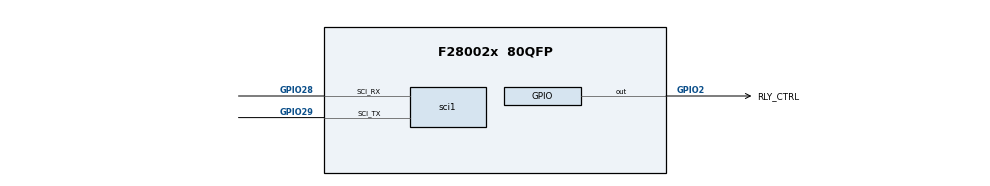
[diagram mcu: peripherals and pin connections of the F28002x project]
/**
 * @cliArgs --device "F28002x" --part "F28002x_80QFP" --package "80QFP" --context "system" --product "C2000WARE@5.04.00.00"
 * @versions {"tool":"1.23.0+4000"}
 */

/**
 * Import the modules used in this configuration.
 */
const adc     = scripting.addModule("/driverlib/adc.js", {}, false);
const adc1    = adc.addInstance();
const adc2    = adc.addInstance();
const asysctl = scripting.addModule("/driverlib/asysctl.js");
const gpio    = scripting.addModule("/driverlib/gpio.js", {}, false);
const gpio1   = gpio.addInstance();
const sci     = scripting.addModule("/driverlib/sci.js", {}, false);
const sci1    = sci.addInstance();

/**
 * Write custom configuration values to the imported modules.
 */
adc1.$name                    = "myADC0";
adc1.adcClockPrescaler        = "ADC_CLK_DIV_2_0";
adc1.interruptPulseMode       = "ADC_PULSE_END_OF_CONV";
adc1.enabledSOCs              = ["ADC_SOC_NUMBER0","ADC_SOC_NUMBER1","ADC_SOC_NUMBER2"];
adc1.soc0Trigger              = "ADC_TRIGGER_EPWM1_SOCA";
adc1.soc1Trigger              = "ADC_TRIGGER_EPWM1_SOCA";
adc1.soc2Trigger              = "ADC_TRIGGER_EPWM1_SOCA";
adc1.soc1Channel              = "ADC_CH_ADCIN1";
adc1.soc2Channel              = "ADC_CH_ADCIN2";
adc1.soc0SampleWindow         = 8;
adc1.soc1SampleWindow         = 8;
adc1.soc2SampleWindow         = 8;
adc1.enabledInts              = ["ADC_INT_NUMBER1"];
adc1.enableInterrupt1         = true;
adc1.interrupt1SOCSource      = "ADC_SOC_NUMBER2";
adc1.registerInterrupts       = ["1"];
adc1.adcInt1.enableInterrupt  = true;
adc1.adcInt1.interruptHandler = "adcA1ISR";

adc2.$name              = "myADC1";
adc2.adcBase            = "ADCC_BASE";
adc2.adcClockPrescaler  = "ADC_CLK_DIV_2_0";
adc2.interruptPulseMode = "ADC_PULSE_END_OF_CONV";
adc2.enabledSOCs        = ["ADC_SOC_NUMBER0","ADC_SOC_NUMBER1","ADC_SOC_NUMBER2"];
adc2.soc0Trigger        = "ADC_TRIGGER_EPWM1_SOCA";
adc2.soc1Trigger        = "ADC_TRIGGER_EPWM1_SOCA";
adc2.soc2Trigger        = "ADC_TRIGGER_EPWM1_SOCA";
adc2.soc0Channel        = "ADC_CH_ADCIN2";
adc2.soc1Channel        = "ADC_CH_ADCIN3";
adc2.soc2Channel        = "ADC_CH_ADCIN4";
adc2.soc0SampleWindow   = 8;
adc2.soc1SampleWindow   = 8;
adc2.soc2SampleWindow   = 8;

const analog  = scripting.addModule("/driverlib/analog.js", {}, false);
const analog1 = analog.addInstance({}, false);
analog1.$name = "myANALOGPinMux0";
adc1.analog   = analog1;
adc2.analog   = analog1;

asysctl.analogReference        = "INTERNAL";
asysctl.analogReferenceVoltage = "1P65";

gpio1.$name             = "RLY_CTRL";
gpio1.direction         = "GPIO_DIR_MODE_OUT";
gpio1.qualMode          = "GPIO_QUAL_ASYNC";
gpio1.writeInitialValue = true;
gpio1.gpioPin.$assign   = "GPIO2";

sci1.$name                 = "mySCI0";
sci1.baudRates             = 230400;
sci1.sci.$assign           = "SCIA";
sci1.sci.sci_rxPin.$assign = "GPIO28";
sci1.sci.sci_txPin.$assign = "GPIO29";
sci1.rxQual.$name          = "myGPIOQUAL0";
sci1.txQual.$name          = "myGPIOQUAL1";

/**
 * Pinmux solution for unlocked pins/peripherals. This ensures that minor changes to the automatic solver in a future
 * version of the tool will not impact the pinmux you originally saw.  These lines can be completely deleted in order to
 * re-solve from scratch.
 */
analog1.analog.$suggestSolution                  = "ANALOG";
analog1.analog["a0/c15Pin"].$suggestSolution     = "A0/C15";
analog1.analog.a1Pin.$suggestSolution            = "A1";
analog1.analog["a10/c10Pin"].$suggestSolution    = "A10/C10";
analog1.analog["a11/c0Pin"].$suggestSolution     = "A11/C0";
analog1.analog["a12/c1Pin"].$suggestSolution     = "A12/C1";
analog1.analog["a14/c4Pin"].$suggestSolution     = "A14/C4";
analog1.analog["a15/c7Pin"].$suggestSolution     = "A15/C7";
analog1.analog["a2/c9Pin"].$suggestSolution      = "A2/C9";
analog1.analog["a3/c5/vdacPin"].$suggestSolution = "A3/C5/VDAC";
analog1.analog["a4/c14Pin"].$suggestSolution     = "A4/C14";
analog1.analog["a5/c2Pin"].$suggestSolution      = "A5/C2";
analog1.analog.a6Pin.$suggestSolution            = "A6";
analog1.analog["a7/c3Pin"].$suggestSolution      = "A7/C3";
analog1.analog["a8/c11Pin"].$suggestSolution     = "A8/C11";
analog1.analog["a9/c8Pin"].$suggestSolution      = "A9/C8";
analog1.analog.c6Pin.$suggestSolution            = "C6";
